# WS53 register map
File version: 0.1.0-experimental
Registers are 32-bit, read-write, no defined reset value unless marked. A register's access mark holds for its fields unless they carry their own. Offsets are from the block's base; [hi:lo] are bit positions.

## I2C0
Base 0x52083000
Same registers: I2C1 0x52084000
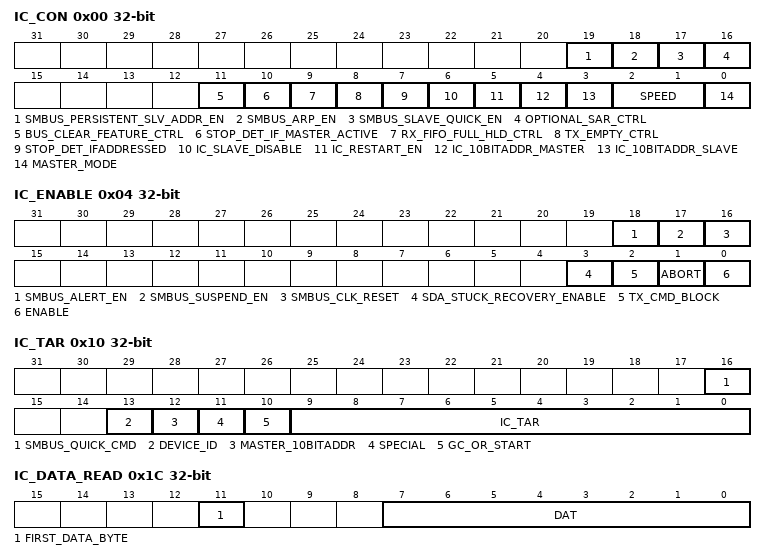
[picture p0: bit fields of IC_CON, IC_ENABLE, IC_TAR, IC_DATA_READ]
0x00 IC_CON
  [19] SMBUS_PERSISTENT_SLV_ADDR_EN, [18] SMBUS_ARP_EN, [17] SMBUS_SLAVE_QUICK_EN, [16] OPTIONAL_SAR_CTRL, [11] BUS_CLEAR_FEATURE_CTRL, [10] STOP_DET_IF_MASTER_ACTIVE, [9] RX_FIFO_FULL_HLD_CTRL, [8] TX_EMPTY_CTRL, [7] STOP_DET_IFADDRESSED, [6] IC_SLAVE_DISABLE, [5] IC_RESTART_EN, [4] IC_10BITADDR_MASTER, [3] IC_10BITADDR_SLAVE, [2:1] SPEED, [0] MASTER_MODE
0x04 IC_ENABLE
  [18] SMBUS_ALERT_EN, [17] SMBUS_SUSPEND_EN, [16] SMBUS_CLK_RESET, [3] SDA_STUCK_RECOVERY_ENABLE, [2] TX_CMD_BLOCK, [1] ABORT, [0] ENABLE
0x10 IC_TAR
  [16] SMBUS_QUICK_CMD, [13] DEVICE_ID, [12] MASTER_10BITADDR, [11] SPECIAL, [10] GC_OR_START, [9:0] IC_TAR
0x14 IC_SAR
  [9:0] IC_SAR
0x18 IC_HS_MADDR
  [2:0] IC_HS_MAR
0x1C IC_DATA_READ ro read-modifies
  [11] FIRST_DATA_BYTE, [7:0] DAT read-has-side-effects
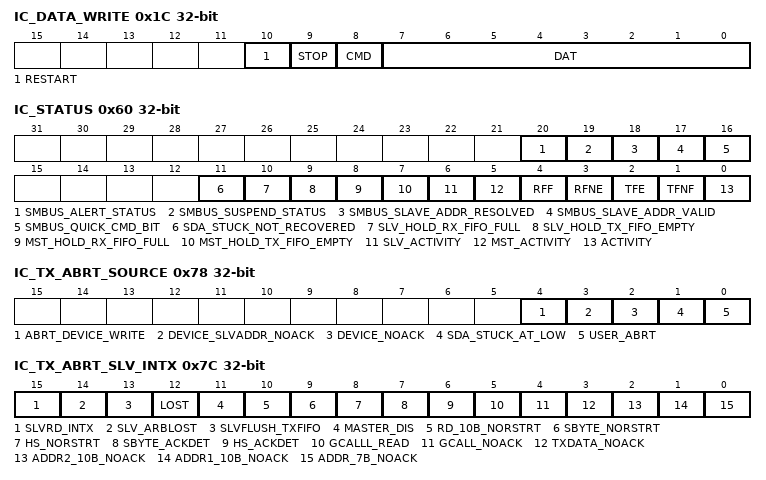
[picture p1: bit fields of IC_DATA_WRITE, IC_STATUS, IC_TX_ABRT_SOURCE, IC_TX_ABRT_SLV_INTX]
0x1C IC_DATA_WRITE wo (alternate view of IC_DATA_READ)
  [10] RESTART, [9] STOP, [8] CMD, [7:0] DAT
0x30 IC_SS_SCL_HCNT
  [15:0] IC_SS_SCL_HCNT
0x34 IC_SS_SCL_LCNT
  [15:0] IC_SS_SCL_LCNT
0x3C IC_FS_SCL_HCNT
  [15:0] IC_FS_SCL_HCNT
0x40 IC_FS_SCL_LCNT
  [15:0] IC_FS_SCL_LCNT
0x44 IC_HS_SCL_HCNT
  [15:0] IC_HS_SCL_HCNT
0x48 IC_HS_SCL_LCNT
  [15:0] IC_HS_SCL_LCNT
0x50 IC_RX_TL
  [7:0] RX_TL
0x54 IC_TX_TL
  [7:0] TX_TL
0x58 IC_SLAVE_DATA_NACK_ONLY
  [0] NACK
0x60 IC_STATUS ro
  [20] SMBUS_ALERT_STATUS, [19] SMBUS_SUSPEND_STATUS, [18] SMBUS_SLAVE_ADDR_RESOLVED, [17] SMBUS_SLAVE_ADDR_VALID, [16] SMBUS_QUICK_CMD_BIT, [11] SDA_STUCK_NOT_RECOVERED, [10] SLV_HOLD_RX_FIFO_FULL, [9] SLV_HOLD_TX_FIFO_EMPTY, [8] MST_HOLD_RX_FIFO_FULL, [7] MST_HOLD_TX_FIFO_EMPTY, [6] SLV_ACTIVITY, [5] MST_ACTIVITY, [4] RFF, [3] RFNE, [2] TFE, [1] TFNF, [0] ACTIVITY
0x64 IC_TXFLR ro
0x68 IC_RXFLR ro
0x6C IC_SDA_RX_HOLD
  [7:0] SDA_RX_HOLD
0x70 IC_SDA_TX_HOLD
  [15:0] SDA_TX_HOLD
0x74 IC_TX_FLUSH_CNT ro
  [8:0] TX_FLUSH_CNT
0x78 IC_TX_ABRT_SOURCE ro
  [4] ABRT_DEVICE_WRITE, [3] DEVICE_SLVADDR_NOACK, [2] DEVICE_NOACK, [1] SDA_STUCK_AT_LOW, [0] USER_ABRT
0x7C IC_TX_ABRT_SLV_INTX ro
  [15] SLVRD_INTX, [14] SLV_ARBLOST, [13] SLVFLUSH_TXFIFO, [12] LOST, [11] MASTER_DIS, [10] RD_10B_NORSTRT, [9] SBYTE_NORSTRT, [8] HS_NORSTRT, [7] SBYTE_ACKDET, [6] HS_ACKDET, [5] GCALLL_READ, [4] GCALL_NOACK, [3] TXDATA_NOACK, [2] ADDR2_10B_NOACK, [1] ADDR1_10B_NOACK, [0] ADDR_7B_NOACK
0x80 IC_ACK_GENERAL_CALL
  [0] ACK_GEN_CALL
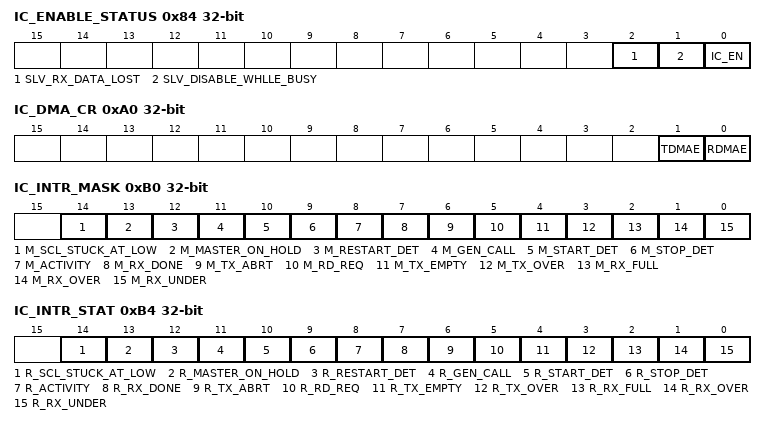
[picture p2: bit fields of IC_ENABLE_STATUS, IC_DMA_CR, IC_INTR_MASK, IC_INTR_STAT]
0x84 IC_ENABLE_STATUS ro
  [2] SLV_RX_DATA_LOST, [1] SLV_DISABLE_WHLLE_BUSY, [0] IC_EN
0xA0 IC_DMA_CR
  [1] TDMAE, [0] RDMAE
0xA4 IC_DMA_TDLR
  [31:0] DMATDL
0xA8 IC_DMA_RDLR
  [31:0] DMARDL
0xAC IC_SDA_SETUP
  [7:0] SDA_SETUP
0xB0 IC_INTR_MASK
  [14] M_SCL_STUCK_AT_LOW, [13] M_MASTER_ON_HOLD, [12] M_RESTART_DET, [11] M_GEN_CALL, [10] M_START_DET, [9] M_STOP_DET, [8] M_ACTIVITY, [7] M_RX_DONE, [6] M_TX_ABRT, [5] M_RD_REQ, [4] M_TX_EMPTY, [3] M_TX_OVER, [2] M_RX_FULL, [1] M_RX_OVER, [0] M_RX_UNDER
0xB4 IC_INTR_STAT ro
  [14] R_SCL_STUCK_AT_LOW, [13] R_MASTER_ON_HOLD, [12] R_RESTART_DET, [11] R_GEN_CALL, [10] R_START_DET, [9] R_STOP_DET, [8] R_ACTIVITY, [7] R_RX_DONE, [6] R_TX_ABRT, [5] R_RD_REQ, [4] R_TX_EMPTY, [3] R_TX_OVER, [2] R_RX_FULL, [1] R_RX_OVER, [0] R_RX_UNDER
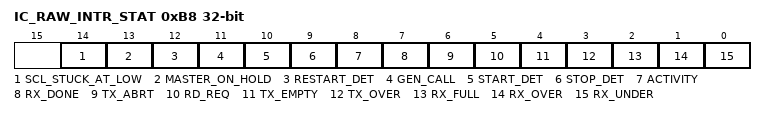
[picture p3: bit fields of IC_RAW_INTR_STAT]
0xB8 IC_RAW_INTR_STAT ro
  [14] SCL_STUCK_AT_LOW, [13] MASTER_ON_HOLD, [12] RESTART_DET, [11] GEN_CALL, [10] START_DET, [9] STOP_DET, [8] ACTIVITY, [7] RX_DONE, [6] TX_ABRT, [5] RD_REQ, [4] TX_EMPTY, [3] TX_OVER, [2] RX_FULL, [1] RX_OVER, [0] RX_UNDER
0xBC IC_INTR_STAT_ALL ro
  [31:0] VALUE — Status slot from SDK struct; no verified software write or individual field semantics
0xC0 IC_CLR_INTR wo
  [31:0] VALUE — Selective clear layout unresolved: SDK bitfield exceeds 32 bits and helper masks disagree with status; do not infer W1C positions or read-clear
0xC4 IC_CLR_INT wo
  [0] CLR_INT range 1..1 — Source clr_all_int writes 1; header says read-clear but conflicts with executed helper; read behavior not exposed
